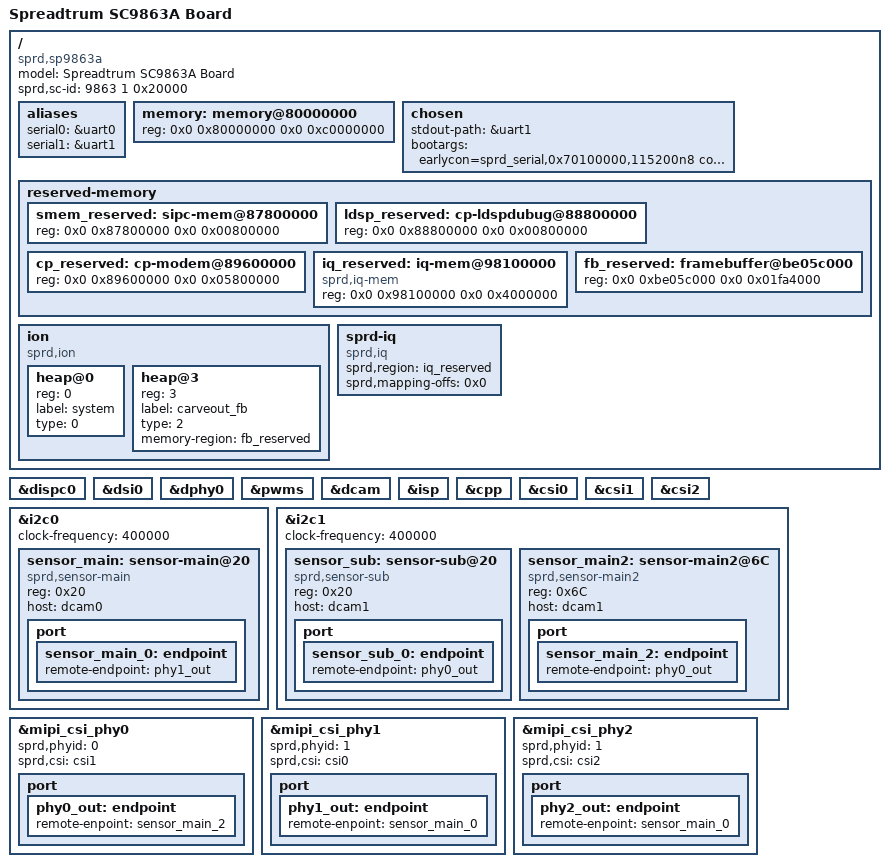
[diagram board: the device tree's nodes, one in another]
/*
 * Spreadtrum sharkl3 board DTS file
 *
 * Copyright (C) 2017, Spreadtrum Communications Inc.
 *
 * This file is licensed under a dual GPLv2 or X11 license.
 */
/dts-v1/;

#include "sc9863a.dtsi"
#include "sp9863a-common.dtsi"

/ {
	model = "Spreadtrum SC9863A Board";

	compatible = "sprd,sp9863a", "sprd,sc9863a";

	sprd,sc-id = <9863 1 0x20000>;

	aliases {
		serial0 = &uart0;
		serial1 = &uart1;
	};

	memory: memory@80000000 {
		device_type = "memory";
		reg = <0x0 0x80000000 0x0 0xc0000000>;
	};

	chosen {
		stdout-path = &uart1;
		bootargs = "earlycon=sprd_serial,0x70100000,115200n8 console=ttyS1,115200n8 loglevel=8 init=/init root=/dev/ram0 rw androidboot.hardware=sp9863a androidboot.selinux=permissive swiotlb=64k";
	};

	reserved-memory {
		#address-cells = <2>;
		#size-cells = <2>;
		ranges;

		smem_reserved: sipc-mem@87800000{
			reg = <0x0 0x87800000 0x0 0x00800000>;
		};

		ldsp_reserved: cp-ldspdubug@88800000 {
			reg = <0x0 0x88800000 0x0 0x00800000>;
		};

		cp_reserved: cp-modem@89600000 {
			reg = <0x0 0x89600000 0x0 0x05800000>;
		};

		/* Only used for iq, will be removed in normal mode by uboot */
		iq_reserved: iq-mem@98100000{
			compatible = "sprd,iq-mem";
			reg = <0x0 0x98100000 0x0 0x4000000>;
		};

		fb_reserved: framebuffer@be05c000{
			reg = <0x0 0xbe05c000 0x0 0x01fa4000>;
		};
	};

	ion {
		compatible = "sprd,ion";
		#address-cells = <1>;
		#size-cells = <0>;

		heap@0 {
			reg = <0>;
			label = "system";
			type = <0>;
		};

		heap@3 {
			reg = <3>;
			label = "carveout_fb";
			type = <2>;
			memory-region = <&fb_reserved>;
		};
	};

	sprd-iq {
		compatible = "sprd,iq";
		sprd,region = <&iq_reserved>;
		sprd,mapping-offs = <0x0>;
	};
};

&dispc0 {
	status = "okay";
};

&dsi0 {
	status = "okay";
};

&dphy0 {
	status = "okay";
};

&pwms {
	status = "okay";
};

&dcam {
	status = "okay";
};

&isp {
	status = "okay";
};

&cpp {
	status = "okay";
};

&csi0 {
	status = "okay";
};

&csi1 {
	status = "okay";
};

&csi2 {
	status = "okay";
};

&i2c0 {
	status = "okay";
	clock-frequency = <400000>;

	sensor_main: sensor-main@20 {
		compatible = "sprd,sensor-main";
		reg = <0x20>;
		host = "dcam0";
		port {
			sensor_main_0: endpoint {
				remote-endpoint = <&phy1_out>;
			};
		};
	};
};

&i2c1 {
	status = "okay";
	clock-frequency = <400000>;

	sensor_sub: sensor-sub@20 {
		compatible = "sprd,sensor-sub";
		reg = <0x20>;
		host = "dcam1";
		port {
			sensor_sub_0: endpoint {
				remote-endpoint = <&phy0_out>;
			};
		};
	};

	sensor_main2: sensor-main2@6C {
		compatible = "sprd,sensor-main2";
		reg = <0x6C>;
		host = "dcam1";
		port {
			sensor_main_2: endpoint {
				remote-endpoint = <&phy0_out>;
			};
		};
	};
};

&mipi_csi_phy0 {
	status = "okay";
	sprd,phyid = <0>;
	sprd,csi = <&csi1>;
	port {
		phy0_out: endpoint {
			remote-enpoint = <&sensor_main_2>;
		};
	};
};

&mipi_csi_phy1 {
	status = "okay";
	sprd,phyid = <1>;
	sprd,csi = <&csi0>;
	port {
		phy1_out: endpoint {
			remote-enpoint = <&sensor_main_0>;
		};
	};
};

&mipi_csi_phy2 {
	status = "okay";
	sprd,phyid = <1>;
	sprd,csi = <&csi2>;
	port {
		phy2_out: endpoint {
			remote-enpoint = <&sensor_main_0>;
		};
	};
};

